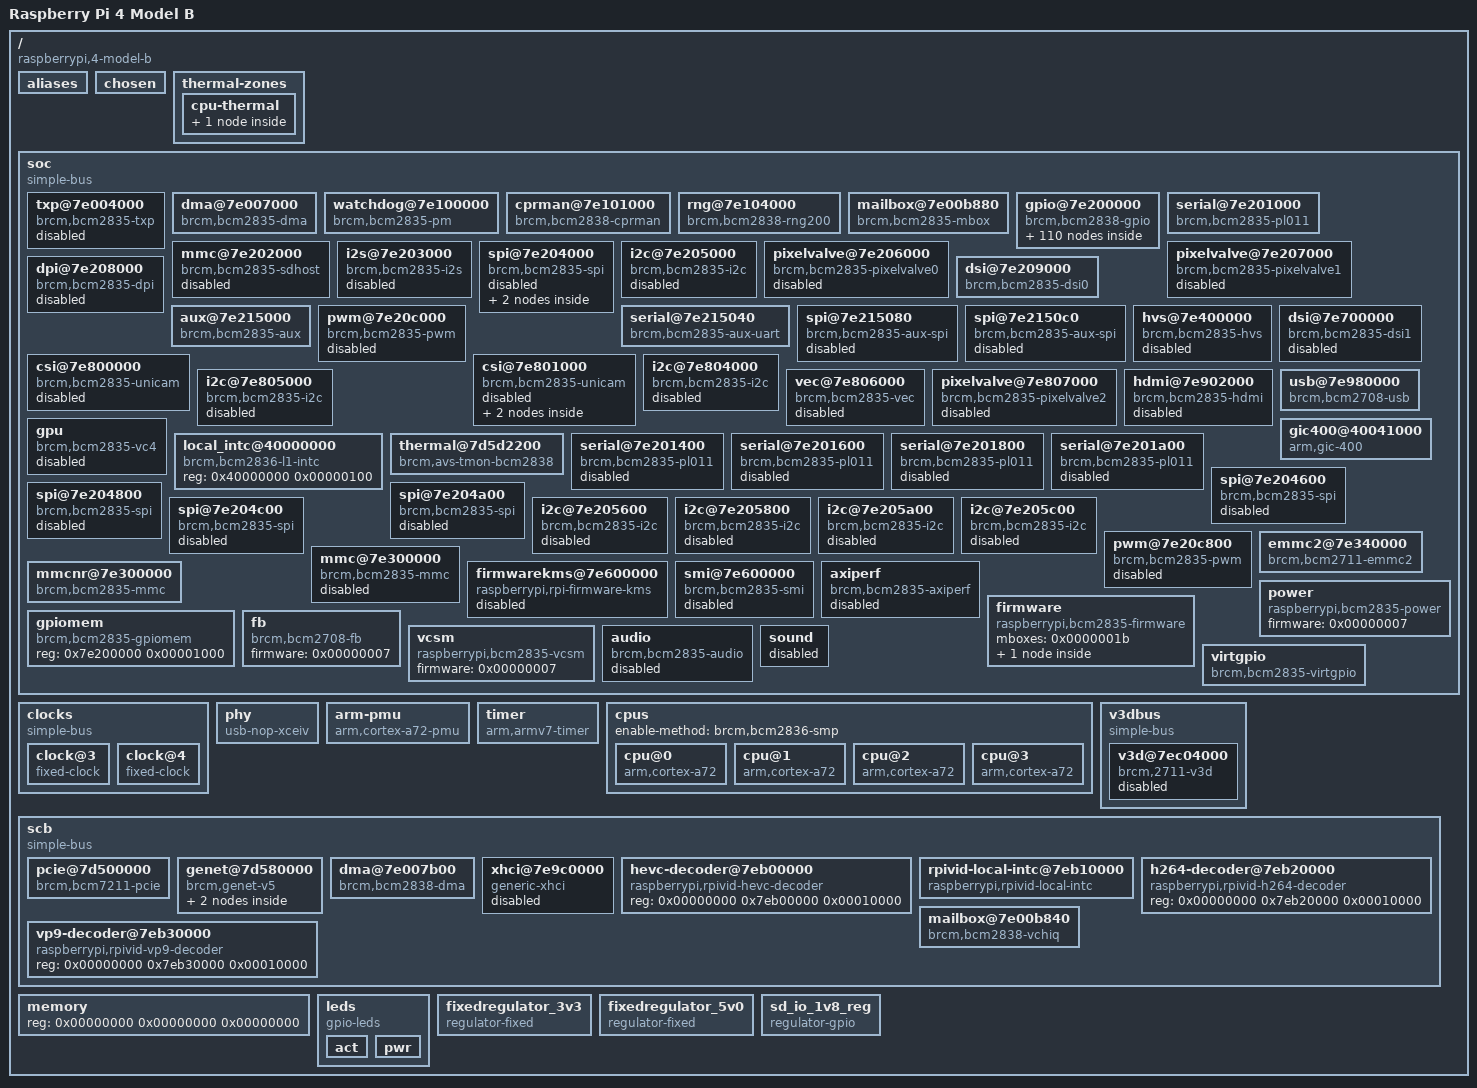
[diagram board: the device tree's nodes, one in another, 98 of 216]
/dts-v1/;
// version:		17
// last_comp_version:	16
// boot_cpuid_phys:	0x0

/memreserve/ 0 0x1000;
/ {
    compatible = "raspberrypi,4-model-b", "brcm,bcm2838";
    model = "Raspberry Pi 4 Model B";
    interrupt-parent = <0x00000001>;
    #address-cells = <0x00000002>;
    #size-cells = <0x00000001>;
    aliases {
        serial0 = "/soc/serial@7e215040";
        serial1 = "/soc/serial@7e201000";
        audio = "/soc/audio";
        aux = "/soc/aux@7e215000";
        sound = "/soc/sound";
        soc = "/soc";
        dma = "/soc/dma@7e007000";
        watchdog = "/soc/watchdog@7e100000";
        random = "/soc/rng@7e104000";
        mailbox = "/soc/mailbox@7e00b880";
        gpio = "/soc/gpio@7e200000";
        uart0 = "/soc/serial@7e201000";
        sdhost = "/soc/mmc@7e202000";
        mmc0 = "/soc/emmc2@7e340000";
        i2s = "/soc/i2s@7e203000";
        spi0 = "/soc/spi@7e204000";
        i2c0 = "/soc/i2c@7e205000";
        uart1 = "/soc/serial@7e215040";
        spi1 = "/soc/spi@7e215080";
        spi2 = "/soc/spi@7e2150c0";
        mmc = "/soc/mmc@7e300000";
        mmc1 = "/soc/mmcnr@7e300000";
        i2c1 = "/soc/i2c@7e804000";
        i2c2 = "/soc/i2c@7e805000";
        usb = "/soc/usb@7e980000";
        leds = "/leds";
        fb = "/soc/fb";
        thermal = "/soc/thermal@7d5d2200";
        axiperf = "/soc/axiperf";
        mmc2 = "/soc/mmc@7e202000";
        i2c3 = "/soc/i2c@7e205600";
        i2c4 = "/soc/i2c@7e205800";
        i2c5 = "/soc/i2c@7e205a00";
        i2c6 = "/soc/i2c@7e205c00";
        ethernet0 = "/scb/genet@7d580000";
    };
    chosen {
        bootargs = "coherent_pool=1M 8250.nr_uarts=1 cma=64M";
    };
    thermal-zones {
        cpu-thermal {
            polling-delay-passive = <0x00000000>;
            polling-delay = <0x000003e8>;
            thermal-sensors = <0x00000002>;
            coefficients = <0xfffffe19 0x000641b8>;
            phandle = <0x00000034>;
            cooling-maps {
            };
        };
    };
    soc {
        compatible = "simple-bus";
        #address-cells = <0x00000001>;
        #size-cells = <0x00000001>;
        ranges = <0x7e000000 0x00000000 0xfe000000 0x01800000 0x7c000000 0x00000000 0xfc000000 0x02000000 0x40000000 0x00000000 0xff800000 0x00800000>;
        dma-ranges = <0xc0000000 0x00000000 0x00000000 0x3c000000>;
        phandle = <0x00000035>;
        txp@7e004000 {
            compatible = "brcm,bcm2835-txp";
            reg = <0x7e004000 0x00000020>;
            interrupts = <0x00000000 0x0000004b 0x00000004>;
            status = "disabled";
            phandle = <0x00000036>;
        };
        dma@7e007000 {
            compatible = "brcm,bcm2835-dma";
            reg = <0x7e007000 0x00000b00>;
            interrupts = <0x00000000 0x00000050 0x00000004 0x00000000 0x00000051 0x00000004 0x00000000 0x00000052 0x00000004 0x00000000 0x00000053 0x00000004 0x00000000 0x00000054 0x00000004 0x00000000 0x00000055 0x00000004 0x00000000 0x00000056 0x00000004 0x00000000 0x00000057 0x00000004 0x00000000 0x00000057 0x00000004 0x00000000 0x00000058 0x00000004 0x00000000 0x00000058 0x00000004>;
            interrupt-names = "dma0", "dma1", "dma2", "dma3", "dma4", "dma5", "dma6", "dma7", "dma8", "dma9", "dma10";
            #dma-cells = <0x00000001>;
            brcm,dma-channel-mask = <0x000001f5>;
            phandle = <0x0000000a>;
        };
        watchdog@7e100000 {
            compatible = "brcm,bcm2835-pm", "brcm,bcm2835-pm-wdt";
            #power-domain-cells = <0x00000001>;
            #reset-cells = <0x00000001>;
            reg = <0x7e100000 0x00000114 0x7e00a000 0x00000024 0x7ec11000 0x00000020>;
            clocks = <0x00000003 0x00000015 0x00000003 0x0000001d 0x00000003 0x00000017 0x00000003 0x00000016>;
            clock-names = "v3d", "peri_image", "h264", "isp";
            system-power-controller;
            phandle = <0x00000021>;
        };
        cprman@7e101000 {
            compatible = "brcm,bcm2838-cprman";
            #clock-cells = <0x00000001>;
            reg = <0x7e101000 0x00002000>;
            clocks = <0x00000004 0x00000005 0x00000000 0x00000005 0x00000001 0x00000005 0x00000002 0x00000006 0x00000000 0x00000006 0x00000001 0x00000006 0x00000002>;
            firmware = <0x00000007>;
            phandle = <0x00000003>;
        };
        rng@7e104000 {
            compatible = "brcm,bcm2838-rng200";
            reg = <0x7e104000 0x00000010>;
            interrupts = <0x00000000 0x0000007d 0x00000004>;
            phandle = <0x0000002b>;
        };
        mailbox@7e00b880 {
            compatible = "brcm,bcm2835-mbox";
            reg = <0x7e00b880 0x00000040>;
            interrupts = <0x00000000 0x00000021 0x00000004>;
            #mbox-cells = <0x00000000>;
            phandle = <0x0000001b>;
        };
        gpio@7e200000 {
            compatible = "brcm,bcm2838-gpio", "brcm,bcm2835-gpio";
            reg = <0x7e200000 0x000000b4>;
            interrupts = <0x00000000 0x00000071 0x00000004 0x00000000 0x00000072 0x00000004>;
            gpio-controller;
            #gpio-cells = <0x00000002>;
            interrupt-controller;
            #interrupt-cells = <0x00000002>;
            pinctrl-names = "default";
            phandle = <0x0000000f>;
            dpi_gpio0 {
                brcm,pins = <0x00000000 0x00000001 0x00000002 0x00000003 0x00000004 0x00000005 0x00000006 0x00000007 0x00000008 0x00000009 0x0000000a 0x0000000b 0x0000000c 0x0000000d 0x0000000e 0x0000000f 0x00000010 0x00000011 0x00000012 0x00000013 0x00000014 0x00000015 0x00000016 0x00000017 0x00000018 0x00000019 0x0000001a 0x0000001b>;
                brcm,function = <0x00000006>;
                phandle = <0x00000037>;
            };
            emmc_gpio22 {
                brcm,pins = <0x00000016 0x00000017 0x00000018 0x00000019 0x0000001a 0x0000001b>;
                brcm,function = <0x00000007>;
                phandle = <0x00000038>;
            };
            emmc_gpio34 {
                brcm,pins = <0x00000022 0x00000023 0x00000024 0x00000025 0x00000026 0x00000027>;
                brcm,function = <0x00000007>;
                brcm,pull = <0x00000000 0x00000002 0x00000002 0x00000002 0x00000002 0x00000002>;
                phandle = <0x00000039>;
            };
            emmc_gpio48 {
                brcm,pins = <0x00000030 0x00000031 0x00000032 0x00000033 0x00000034 0x00000035>;
                brcm,function = <0x00000007>;
                phandle = <0x00000019>;
            };
            gpclk0_gpio4 {
                brcm,pins = <0x00000004>;
                brcm,function = <0x00000004>;
                phandle = <0x0000003a>;
            };
            gpclk1_gpio5 {
                brcm,pins = <0x00000005>;
                brcm,function = <0x00000004>;
                phandle = <0x0000003b>;
            };
            gpclk1_gpio42 {
                brcm,pins = <0x0000002a>;
                brcm,function = <0x00000004>;
                phandle = <0x0000003c>;
            };
            gpclk1_gpio44 {
                brcm,pins = <0x0000002c>;
                brcm,function = <0x00000004>;
                phandle = <0x0000003d>;
            };
            gpclk2_gpio6 {
                brcm,pins = <0x00000006>;
                brcm,function = <0x00000004>;
                phandle = <0x0000003e>;
            };
            gpclk2_gpio43 {
                brcm,pins = <0x0000002b>;
                brcm,function = <0x00000004>;
                brcm,pull = <0x00000000>;
                phandle = <0x0000003f>;
            };
            i2c0_gpio0 {
                brcm,pins = <0x00000000 0x00000001>;
                brcm,function = <0x00000004>;
                phandle = <0x00000040>;
            };
            i2c0_gpio28 {
                brcm,pins = <0x0000001c 0x0000001d>;
                brcm,function = <0x00000004>;
                phandle = <0x00000041>;
            };
            i2c0_gpio44 {
                brcm,pins = <0x0000002c 0x0000002d>;
                brcm,function = <0x00000005>;
                phandle = <0x00000042>;
            };
            i2c1_gpio2 {
                brcm,pins = <0x00000002 0x00000003>;
                brcm,function = <0x00000004>;
                phandle = <0x00000043>;
            };
            i2c1_gpio44 {
                brcm,pins = <0x0000002c 0x0000002d>;
                brcm,function = <0x00000006>;
                phandle = <0x00000044>;
            };
            jtag_gpio22 {
                brcm,pins = <0x00000016 0x00000017 0x00000018 0x00000019 0x0000001a 0x0000001b>;
                brcm,function = <0x00000003>;
                phandle = <0x00000045>;
            };
            pcm_gpio18 {
                brcm,pins = <0x00000012 0x00000013 0x00000014 0x00000015>;
                brcm,function = <0x00000004>;
                phandle = <0x00000046>;
            };
            pcm_gpio28 {
                brcm,pins = <0x0000001c 0x0000001d 0x0000001e 0x0000001f>;
                brcm,function = <0x00000006>;
                phandle = <0x00000047>;
            };
            pwm0_gpio12 {
                brcm,pins = <0x0000000c>;
                brcm,function = <0x00000004>;
                phandle = <0x00000048>;
            };
            pwm0_gpio18 {
                brcm,pins = <0x00000012>;
                brcm,function = <0x00000002>;
                phandle = <0x00000049>;
            };
            pwm0_gpio40 {
                brcm,pins = <0x00000028>;
                brcm,function = <0x00000004>;
                phandle = <0x0000004a>;
            };
            pwm1_gpio13 {
                brcm,pins = <0x0000000d>;
                brcm,function = <0x00000004>;
                phandle = <0x0000004b>;
            };
            pwm1_gpio19 {
                brcm,pins = <0x00000013>;
                brcm,function = <0x00000002>;
                phandle = <0x0000004c>;
            };
            pwm1_gpio41 {
                brcm,pins = <0x00000029>;
                brcm,function = <0x00000004>;
                phandle = <0x0000004d>;
            };
            pwm1_gpio45 {
                brcm,pins = <0x0000002d>;
                brcm,function = <0x00000004>;
                phandle = <0x0000004e>;
            };
            sdhost_gpio48 {
                brcm,pins = <0x00000016 0x00000017 0x00000018 0x00000019 0x0000001a 0x0000001b>;
                brcm,function = <0x00000004>;
                phandle = <0x0000000b>;
            };
            spi0_gpio7 {
                brcm,pins = <0x00000007 0x00000008 0x00000009 0x0000000a 0x0000000b>;
                brcm,function = <0x00000004>;
                phandle = <0x0000004f>;
            };
            spi0_gpio35 {
                brcm,pins = <0x00000023 0x00000024 0x00000025 0x00000026 0x00000027>;
                brcm,function = <0x00000004>;
                phandle = <0x00000050>;
            };
            spi1_gpio16 {
                brcm,pins = <0x00000010 0x00000011 0x00000012 0x00000013 0x00000014 0x00000015>;
                brcm,function = <0x00000003>;
                phandle = <0x00000051>;
            };
            spi2_gpio40 {
                brcm,pins = <0x00000028 0x00000029 0x0000002a 0x0000002b 0x0000002c 0x0000002d>;
                brcm,function = <0x00000003>;
                phandle = <0x00000052>;
            };
            uart0_gpio14 {
                brcm,pins = <0x0000000e 0x0000000f>;
                brcm,function = <0x00000004>;
                phandle = <0x00000053>;
            };
            uart0_ctsrts_gpio16 {
                brcm,pins = <0x00000010 0x00000011>;
                brcm,function = <0x00000007>;
                phandle = <0x00000054>;
            };
            uart0_ctsrts_gpio30 {
                brcm,pins = <0x0000001e 0x0000001f>;
                brcm,function = <0x00000007>;
                brcm,pull = <0x00000002 0x00000000>;
                phandle = <0x00000055>;
            };
            uart0_gpio32 {
                brcm,pins = <0x00000020 0x00000021>;
                brcm,function = <0x00000007>;
                brcm,pull = <0x00000000 0x00000002>;
                phandle = <0x00000056>;
            };
            uart0_gpio36 {
                brcm,pins = <0x00000024 0x00000025>;
                brcm,function = <0x00000006>;
                phandle = <0x00000057>;
            };
            uart0_ctsrts_gpio38 {
                brcm,pins = <0x00000026 0x00000027>;
                brcm,function = <0x00000006>;
                phandle = <0x00000058>;
            };
            uart1_gpio14 {
                brcm,pins = <0x0000000e 0x0000000f>;
                brcm,function = <0x00000002>;
                phandle = <0x00000059>;
            };
            uart1_ctsrts_gpio16 {
                brcm,pins = <0x00000010 0x00000011>;
                brcm,function = <0x00000002>;
                phandle = <0x0000005a>;
            };
            uart1_gpio32 {
                brcm,pins = <0x00000020 0x00000021>;
                brcm,function = <0x00000002>;
                phandle = <0x0000005b>;
            };
            uart1_ctsrts_gpio30 {
                brcm,pins = <0x0000001e 0x0000001f>;
                brcm,function = <0x00000002>;
                phandle = <0x0000005c>;
            };
            uart1_gpio40 {
                brcm,pins = <0x00000028 0x00000029>;
                brcm,function = <0x00000002>;
                phandle = <0x0000005d>;
            };
            uart1_ctsrts_gpio42 {
                brcm,pins = <0x0000002a 0x0000002b>;
                brcm,function = <0x00000002>;
                phandle = <0x0000005e>;
            };
            gpclk0_gpio49 {
                brcm,pins = <0x00000031>;
                brcm,function = <0x00000005>;
                brcm,pull = <0x00000000>;
                phandle = <0x0000005f>;
            };
            gpclk1_gpio50 {
                brcm,pins = <0x00000032>;
                brcm,function = <0x00000005>;
                brcm,pull = <0x00000000>;
                phandle = <0x00000060>;
            };
            gpclk2_gpio51 {
                brcm,pins = <0x00000033>;
                brcm,function = <0x00000005>;
                brcm,pull = <0x00000000>;
                phandle = <0x00000061>;
            };
            i2c0_gpio46 {
                brcm,pins = <0x0000002e 0x0000002f>;
                brcm,function = <0x00000004>;
                phandle = <0x00000062>;
            };
            i2c1_gpio46 {
                brcm,pins = <0x0000002e 0x0000002f>;
                brcm,function = <0x00000005>;
                phandle = <0x00000063>;
            };
            i2c3_gpio2 {
                brcm,pins = <0x00000002 0x00000003>;
                brcm,function = <0x00000002>;
                phandle = <0x00000064>;
            };
            i2c3_gpio4 {
                brcm,pins = <0x00000004 0x00000005>;
                brcm,function = <0x00000002>;
                phandle = <0x00000065>;
            };
            i2c4_gpio6 {
                brcm,pins = <0x00000006 0x00000007>;
                brcm,function = <0x00000002>;
                phandle = <0x00000066>;
            };
            i2c4_gpio8 {
                brcm,pins = <0x00000008 0x00000009>;
                brcm,function = <0x00000002>;
                phandle = <0x00000067>;
            };
            i2c5_gpio10 {
                brcm,pins = <0x0000000a 0x0000000b>;
                brcm,function = <0x00000002>;
                phandle = <0x00000068>;
            };
            i2c5_gpio12 {
                brcm,pins = <0x0000000c 0x0000000d>;
                brcm,function = <0x00000002>;
                phandle = <0x00000069>;
            };
            i2c6_gpio0 {
                brcm,pins = <0x00000000 0x00000001>;
                brcm,function = <0x00000002>;
                phandle = <0x0000006a>;
            };
            i2c6_gpio22 {
                brcm,pins = <0x00000016 0x00000017>;
                brcm,function = <0x00000002>;
                phandle = <0x0000006b>;
            };
            i2c_slave_gpio8 {
                brcm,pins = <0x00000008 0x00000009 0x0000000a 0x0000000b>;
                brcm,function = <0x00000007>;
                phandle = <0x0000006c>;
            };
            jtag_gpio48 {
                brcm,pins = <0x00000030 0x00000031 0x00000032 0x00000033 0x00000034 0x00000035>;
                brcm,function = <0x00000003>;
                phandle = <0x0000006d>;
            };
            mii_gpio28 {
                brcm,pins = <0x0000001c 0x0000001d 0x0000001e 0x0000001f>;
                brcm,function = <0x00000003>;
                phandle = <0x0000006e>;
            };
            mii_gpio36 {
                brcm,pins = <0x00000024 0x00000025 0x00000026 0x00000027>;
                brcm,function = <0x00000002>;
                phandle = <0x0000006f>;
            };
            pcm_gpio50 {
                brcm,pins = <0x00000032 0x00000033 0x00000034 0x00000035>;
                brcm,function = <0x00000006>;
                phandle = <0x00000070>;
            };
            pwm0_gpio52 {
                brcm,pins = <0x00000034>;
                brcm,function = <0x00000005>;
                brcm,pull = <0x00000000>;
                phandle = <0x00000071>;
            };
            pwm1_gpio53 {
                brcm,pins = <0x00000035>;
                brcm,function = <0x00000005>;
                brcm,pull = <0x00000000>;
                phandle = <0x00000072>;
            };
            rgmii_gpio35 {
                brcm,pins = <0x00000023 0x00000024>;
                brcm,function = <0x00000003>;
                phandle = <0x00000073>;
            };
            rgmii_irq_gpio34 {
                brcm,pins = <0x00000022>;
                brcm,function = <0x00000002>;
                phandle = <0x00000074>;
            };
            rgmii_irq_gpio39 {
                brcm,pins = <0x00000027>;
                brcm,function = <0x00000003>;
                phandle = <0x00000075>;
            };
            rgmii_mdio_gpio28 {
                brcm,pins = <0x0000001c 0x0000001d>;
                brcm,function = <0x00000002>;
                phandle = <0x00000076>;
            };
            rgmii_mdio_gpio37 {
                brcm,pins = <0x00000025 0x00000026>;
                brcm,function = <0x00000003>;
                phandle = <0x00000077>;
            };
            spi0_gpio46 {
                brcm,pins = <0x0000002e 0x0000002f 0x00000030 0x00000031>;
                brcm,function = <0x00000006>;
                phandle = <0x00000078>;
            };
            spi2_gpio46 {
                brcm,pins = <0x0000002e 0x0000002f 0x00000030 0x00000031 0x00000032>;
                brcm,function = <0x00000002>;
                phandle = <0x00000079>;
            };
            spi3_gpio0 {
                brcm,pins = <0x00000000 0x00000001 0x00000002 0x00000003>;
                brcm,function = <0x00000007>;
                phandle = <0x0000007a>;
            };
            spi4_gpio4 {
                brcm,pins = <0x00000004 0x00000005 0x00000006 0x00000007>;
                brcm,function = <0x00000007>;
                phandle = <0x0000007b>;
            };
            spi5_gpio12 {
                brcm,pins = <0x0000000c 0x0000000d 0x0000000e 0x0000000f>;
                brcm,function = <0x00000007>;
                phandle = <0x0000007c>;
            };
            spi6_gpio18 {
                brcm,pins = <0x00000012 0x00000013 0x00000014 0x00000015>;
                brcm,function = <0x00000007>;
                phandle = <0x0000007d>;
            };
            uart2_gpio0 {
                brcm,pins = <0x00000000 0x00000001>;
                brcm,function = <0x00000003>;
                brcm,pull = <0x00000000 0x00000002>;
                phandle = <0x0000007e>;
            };
            uart2_ctsrts_gpio2 {
                brcm,pins = <0x00000002 0x00000003>;
                brcm,function = <0x00000003>;
                brcm,pull = <0x00000002 0x00000000>;
                phandle = <0x0000007f>;
            };
            uart3_gpio4 {
                brcm,pins = <0x00000004 0x00000005>;
                brcm,function = <0x00000003>;
                brcm,pull = <0x00000000 0x00000002>;
                phandle = <0x00000080>;
            };
            uart3_ctsrts_gpio6 {
                brcm,pins = <0x00000006 0x00000007>;
                brcm,function = <0x00000003>;
                brcm,pull = <0x00000002 0x00000000>;
                phandle = <0x00000081>;
            };
            uart4_gpio8 {
                brcm,pins = <0x00000008 0x00000009>;
                brcm,function = <0x00000003>;
                brcm,pull = <0x00000000 0x00000002>;
                phandle = <0x00000082>;
            };
            uart4_ctsrts_gpio10 {
                brcm,pins = <0x0000000a 0x0000000b>;
                brcm,function = <0x00000003>;
                brcm,pull = <0x00000002 0x00000000>;
                phandle = <0x00000083>;
            };
            uart5_gpio12 {
                brcm,pins = <0x0000000c 0x0000000d>;
                brcm,function = <0x00000003>;
                brcm,pull = <0x00000000 0x00000002>;
                phandle = <0x00000084>;
            };
            uart5_ctsrts_gpio14 {
                brcm,pins = <0x0000000e 0x0000000f>;
                brcm,function = <0x00000003>;
                brcm,pull = <0x00000002 0x00000000>;
                phandle = <0x00000085>;
            };
            dpi_18bit_gpio0 {
                brcm,pins = <0x00000000 0x00000001 0x00000002 0x00000003 0x00000004 0x00000005 0x00000006 0x00000007 0x00000008 0x00000009 0x0000000a 0x0000000b 0x0000000c 0x0000000d 0x0000000e 0x0000000f 0x00000010 0x00000011 0x00000012 0x00000013 0x00000014 0x00000015>;
                brcm,function = <0x00000006>;
                phandle = <0x00000086>;
            };
            gpioout {
                brcm,pins = <0x00000006>;
                brcm,function = <0x00000001>;
                phandle = <0x00000087>;
            };
            alt0 {
                brcm,pins = <0x00000004 0x00000005 0x00000007 0x00000008 0x00000009 0x0000000a 0x0000000b>;
                brcm,function = <0x00000004>;
                phandle = <0x00000088>;
            };
            spi0_pins {
                brcm,pins = <0x00000009 0x0000000a 0x0000000b>;
                brcm,function = <0x00000004>;
                phandle = <0x0000000d>;
            };
            spi0_cs_pins {
                brcm,pins = <0x00000008 0x00000007>;
                brcm,function = <0x00000001>;
                phandle = <0x0000000e>;
            };
            spi3_pins {
                brcm,pins = <0x00000001 0x00000002 0x00000003>;
                brcm,function = <0x00000007>;
                phandle = <0x00000089>;
            };
            spi3_cs_pins {
                brcm,pins = <0x00000000 0x00000018>;
                brcm,function = <0x00000001>;
                phandle = <0x0000008a>;
            };
            spi4_pins {
                brcm,pins = <0x00000005 0x00000006 0x00000007>;
                brcm,function = <0x00000007>;
                phandle = <0x0000008b>;
            };
            spi4_cs_pins {
                brcm,pins = <0x00000004 0x00000019>;
                brcm,function = <0x00000001>;
                phandle = <0x0000008c>;
            };
            spi5_pins {
                brcm,pins = <0x0000000d 0x0000000e 0x0000000f>;
                brcm,function = <0x00000007>;
                phandle = <0x0000008d>;
            };
            spi5_cs_pins {
                brcm,pins = <0x0000000c 0x0000001a>;
                brcm,function = <0x00000001>;
                phandle = <0x0000008e>;
            };
            spi6_pins {
                brcm,pins = <0x00000013 0x00000014 0x00000015>;
                brcm,function = <0x00000007>;
                phandle = <0x0000008f>;
            };
            spi6_cs_pins {
                brcm,pins = <0x00000012 0x0000001b>;
                brcm,function = <0x00000001>;
                phandle = <0x00000090>;
            };
            i2c0 {
                brcm,pins = <0x00000000 0x00000001>;
                brcm,function = <0x00000004>;
                brcm,pull = <0x00000002>;
                phandle = <0x00000010>;
            };
            i2c1 {
                brcm,pins = <0x00000002 0x00000003>;
                brcm,function = <0x00000004>;
                brcm,pull = <0x00000002>;
                phandle = <0x00000014>;
            };
            i2c3 {
                brcm,pins = <0x00000004 0x00000005>;
                brcm,function = <0x00000002>;
                brcm,pull = <0x00000002>;
                phandle = <0x00000091>;
            };
            i2c4 {
                brcm,pins = <0x00000008 0x00000009>;
                brcm,function = <0x00000002>;
                brcm,pull = <0x00000002>;
                phandle = <0x00000092>;
            };
            i2c5 {
                brcm,pins = <0x0000000c 0x0000000d>;
                brcm,function = <0x00000002>;
                brcm,pull = <0x00000002>;
                phandle = <0x00000093>;
            };
            i2c6 {
                brcm,pins = <0x00000016 0x00000017>;
                brcm,function = <0x00000002>;
                brcm,pull = <0x00000002>;
                phandle = <0x00000094>;
            };
            i2s {
                brcm,pins = <0x00000012 0x00000013 0x00000014 0x00000015>;
                brcm,function = <0x00000004>;
                phandle = <0x0000000c>;
            };
            sdio_pins {
                brcm,pins = <0x00000022 0x00000023 0x00000024 0x00000025 0x00000026 0x00000027>;
                brcm,function = <0x00000007>;
                brcm,pull = <0x00000000 0x00000002 0x00000002 0x00000002 0x00000002 0x00000002>;
                phandle = <0x0000001a>;
            };
            bt_pins {
                brcm,pins = "-";
                brcm,function = <0x00000000>;
                brcm,pull = <0x00000002>;
                phandle = <0x00000009>;
            };
            uart0_pins {
                brcm,pins = <0x00000020 0x00000021>;
                brcm,function = <0x00000007>;
                brcm,pull = <0x00000000 0x00000002>;
                phandle = <0x00000008>;
            };
            uart1_pins {
                brcm,pins;
                brcm,function;
                brcm,pull;
                phandle = <0x00000013>;
            };
            uart2_pins {
                brcm,pins = <0x00000000 0x00000001>;
                brcm,function = <0x00000003>;
                brcm,pull = <0x00000000 0x00000002>;
                phandle = <0x00000095>;
            };
            uart3_pins {
                brcm,pins = <0x00000004 0x00000005>;
                brcm,function = <0x00000003>;
                brcm,pull = <0x00000000 0x00000002>;
                phandle = <0x00000096>;
            };
            uart4_pins {
                brcm,pins = <0x00000008 0x00000009>;
                brcm,function = <0x00000003>;
                brcm,pull = <0x00000000 0x00000002>;
                phandle = <0x00000097>;
            };
            uart5_pins {
                brcm,pins = <0x0000000c 0x0000000d>;
                brcm,function = <0x00000003>;
                brcm,pull = <0x00000000 0x00000002>;
                phandle = <0x00000098>;
            };
            audio_pins {
                brcm,pins = <0x00000028 0x00000029>;
                brcm,function = <0x00000004>;
                phandle = <0x0000001c>;
            };
        };
        serial@7e201000 {
            compatible = "brcm,bcm2835-pl011", "arm,pl011", "arm,primecell";
            reg = <0x7e201000 0x00000200>;
            interrupts = <0x00000000 0x00000079 0x00000004>;
            clocks = <0x00000003 0x00000013 0x00000003 0x00000014>;
            clock-names = "uartclk", "apb_pclk";
            arm,primecell-periphid = <0x00241011>;
            cts-event-workaround;
            pinctrl-names = "default";
            pinctrl-0 = <0x00000008 0x00000009>;
            status = "okay";
            phandle = <0x00000024>;
        };
        mmc@7e202000 {
            compatible = "brcm,bcm2835-sdhost";
            reg = <0x7e202000 0x00000100>;
            interrupts = <0x00000000 0x00000078 0x00000004>;
            clocks = <0x00000003 0x00000014>;
            dmas = <0x0000000a 0x2000000d>;
            dma-names = "rx-tx";
            status = "disabled";
            pinctrl-names = "default";
            pinctrl-0 = <0x0000000b>;
            bus-width = <0x00000004>;
            brcm,overclock-50 = <0x00000000>;
            brcm,pio-limit = <0x00000001>;
            phandle = <0x0000002c>;
        };
        i2s@7e203000 {
            compatible = "brcm,bcm2835-i2s";
            reg = <0x7e203000 0x00000024>;
            clocks = <0x00000003 0x0000001f>;
            dmas = <0x0000000a 0x00000002 0x0000000a 0x00000003>;
            dma-names = "tx", "rx";
            status = "disabled";
            #sound-dai-cells = <0x00000000>;
            pinctrl-names = "default";
            pinctrl-0 = <0x0000000c>;
            phandle = <0x00000026>;
        };
        spi@7e204000 {
            compatible = "brcm,bcm2835-spi";
            reg = <0x7e204000 0x00000200>;
            interrupts = <0x00000000 0x00000076 0x00000004>;
            clocks = <0x00000003 0x00000014>;
            #address-cells = <0x00000001>;
            #size-cells = <0x00000000>;
            status = "disabled";
            dmas = <0x0000000a 0x00000006 0x0000000a 0x00000007>;
            dma-names = "tx", "rx";
            pinctrl-names = "default";
            pinctrl-0 = <0x0000000d 0x0000000e>;
            cs-gpios = <0x0000000f 0x00000008 0x00000001 0x0000000f 0x00000007 0x00000001>;
            phandle = <0x00000027>;
            spidev@0 {
                compatible = "spidev";
                reg = <0x00000000>;
                #address-cells = <0x00000001>;
                #size-cells = <0x00000000>;
                spi-max-frequency = <0x07735940>;
                phandle = <0x00000099>;
            };
            spidev@1 {
                compatible = "spidev";
                reg = <0x00000001>;
                #address-cells = <0x00000001>;
                #size-cells = <0x00000000>;
                spi-max-frequency = <0x07735940>;
                phandle = <0x0000009a>;
            };
        };
        i2c@7e205000 {
            compatible = "brcm,bcm2835-i2c";
            reg = <0x7e205000 0x00000200>;
            interrupts = <0x00000000 0x00000075 0x00000004>;
            clocks = <0x00000003 0x00000014>;
            #address-cells = <0x00000001>;
            #size-cells = <0x00000000>;
            status = "disabled";
            pinctrl-names = "default";
            pinctrl-0 = <0x00000010>;
            clock-frequency = <0x000186a0>;
            phandle = <0x00000028>;
        };
        pixelvalve@7e206000 {
            compatible = "brcm,bcm2835-pixelvalve0";
            reg = <0x7e206000 0x00000100>;
            interrupts = <0x00000000 0x0000006d 0x00000004>;
            status = "disabled";
            phandle = <0x0000009b>;
        };
        pixelvalve@7e207000 {
            compatible = "brcm,bcm2835-pixelvalve1";
            reg = <0x7e207000 0x00000100>;
            interrupts = <0x00000000 0x0000006e 0x00000004>;
            status = "disabled";
            phandle = <0x0000009c>;
        };
        dpi@7e208000 {
            compatible = "brcm,bcm2835-dpi";
            reg = <0x7e208000 0x0000008c>;
            clocks = <0x00000003 0x00000014 0x00000003 0x0000002c>;
            clock-names = "core", "pixel";
            #address-cells = <0x00000001>;
            #size-cells = <0x00000000>;
            status = "disabled";
            phandle = <0x0000009d>;
        };
        dsi@7e209000 {
            compatible = "brcm,bcm2835-dsi0";
            reg = <0x7e209000 0x00000078>;
            interrupts = <0x00000000 0x00000064 0x00000004>;
            #address-cells = <0x00000001>;
            #size-cells = <0x00000000>;
            #clock-cells = <0x00000001>;
            clocks = <0x00000003 0x00000020 0x00000003 0x0000002f 0x00000003 0x00000031>;
            clock-names = "phy", "escape", "pixel";
            clock-output-names = "dsi0_byte", "dsi0_ddr2", "dsi0_ddr";
            power-domains = <0x00000011 0x00000011>;
            phandle = <0x00000005>;
        };
        aux@7e215000 {
            compatible = "brcm,bcm2835-aux";
            #clock-cells = <0x00000001>;
            reg = <0x7e215000 0x00000008>;
            clocks = <0x00000003 0x00000014>;
            phandle = <0x00000012>;
        };
        serial@7e215040 {
            compatible = "brcm,bcm2835-aux-uart";
            reg = <0x7e215040 0x00000040>;
            interrupts = <0x00000000 0x0000005d 0x00000004>;
            clocks = <0x00000012 0x00000000>;
            status = "okay";
            pinctrl-names = "default";
            pinctrl-0 = <0x00000013>;
            phandle = <0x00000025>;
        };
        spi@7e215080 {
            compatible = "brcm,bcm2835-aux-spi";
            reg = <0x7e215080 0x00000040>;
            interrupts = <0x00000000 0x0000005d 0x00000004>;
            clocks = <0x00000012 0x00000001>;
            #address-cells = <0x00000001>;
            #size-cells = <0x00000000>;
            status = "disabled";
            phandle = <0x0000009e>;
        };
        spi@7e2150c0 {
            compatible = "brcm,bcm2835-aux-spi";
            reg = <0x7e2150c0 0x00000040>;
            interrupts = <0x00000000 0x0000005d 0x00000004>;
            clocks = <0x00000012 0x00000002>;
            #address-cells = <0x00000001>;
            #size-cells = <0x00000000>;
            status = "disabled";
            phandle = <0x0000009f>;
        };
        pwm@7e20c000 {
            compatible = "brcm,bcm2835-pwm";
            reg = <0x7e20c000 0x00000028>;
            clocks = <0x00000003 0x0000001e>;
            assigned-clocks = <0x00000003 0x0000001e>;
            assigned-clock-rates = <0x00989680>;
            #pwm-cells = <0x00000002>;
            status = "disabled";
            phandle = <0x000000a0>;
        };
        hvs@7e400000 {
            compatible = "brcm,bcm2835-hvs";
            reg = <0x7e400000 0x00006000>;
            interrupts = <0x00000000 0x00000061 0x00000004>;
            status = "disabled";
            phandle = <0x000000a1>;
        };
        dsi@7e700000 {
            compatible = "brcm,bcm2835-dsi1";
            reg = <0x7e700000 0x0000008c>;
            interrupts = <0x00000000 0x0000006c 0x00000004>;
            #address-cells = <0x00000001>;
            #size-cells = <0x00000000>;
            #clock-cells = <0x00000001>;
            clocks = <0x00000003 0x00000023 0x00000003 0x00000030 0x00000003 0x00000032>;
            clock-names = "phy", "escape", "pixel";
            clock-output-names = "dsi1_byte", "dsi1_ddr2", "dsi1_ddr";
            status = "disabled";
            power-domains = <0x00000011 0x00000012>;
            phandle = <0x00000006>;
        };
        csi@7e800000 {
            compatible = "brcm,bcm2835-unicam";
            reg = <0x7e800000 0x00000800 0x7e802000 0x00000004>;
            interrupts = <0x00000000 0x00000066 0x00000004>;
            clocks = <0x00000003 0x0000002d>;
            clock-names = "lp";
            #address-cells = <0x00000001>;
            #size-cells = <0x00000000>;
            #clock-cells = <0x00000001>;
            status = "disabled";
            power-domains = <0x00000011 0x0000000c>;
            phandle = <0x000000a2>;
        };
        csi@7e801000 {
            compatible = "brcm,bcm2835-unicam";
            reg = <0x7e801000 0x00000800 0x7e802004 0x00000004>;
            interrupts = <0x00000000 0x00000067 0x00000004>;
            clocks = <0x00000003 0x0000002e>;
            clock-names = "lp";
            #address-cells = <0x00000001>;
            #size-cells = <0x00000000>;
            #clock-cells = <0x00000001>;
            status = "disabled";
            power-domains = <0x00000011 0x0000000d>;
            phandle = <0x000000a3>;
            port {
                endpoint {
                    data-lanes = <0x00000001 0x00000002>;
                };
            };
        };
        i2c@7e804000 {
            compatible = "brcm,bcm2835-i2c";
            reg = <0x7e804000 0x00001000>;
            interrupts = <0x00000000 0x00000075 0x00000004>;
            clocks = <0x00000003 0x00000014>;
            #address-cells = <0x00000001>;
            #size-cells = <0x00000000>;
            status = "disabled";
            pinctrl-names = "default";
            pinctrl-0 = <0x00000014>;
            clock-frequency = <0x000186a0>;
            phandle = <0x00000029>;
        };
        i2c@7e805000 {
            compatible = "brcm,bcm2835-i2c";
            reg = <0x7e805000 0x00001000>;
            interrupts = <0x00000000 0x00000075 0x00000004>;
            clocks = <0x00000003 0x00000014>;
            #address-cells = <0x00000001>;
            #size-cells = <0x00000000>;
            status = "disabled";
            clock-frequency = <0x000186a0>;
            phandle = <0x00000015>;
        };
        vec@7e806000 {
            compatible = "brcm,bcm2835-vec";
            reg = <0x7e806000 0x00001000>;
            clocks = <0x00000003 0x00000018>;
            interrupts = <0x00000000 0x0000007b 0x00000004>;
            status = "disabled";
            power-domains = <0x00000011 0x00000007>;
            phandle = <0x000000a4>;
        };
        pixelvalve@7e807000 {
            compatible = "brcm,bcm2835-pixelvalve2";
            reg = <0x7e807000 0x00000100>;
            interrupts = <0x00000000 0x0000006a 0x00000004>;
            status = "disabled";
            phandle = <0x000000a5>;
        };
        hdmi@7e902000 {
            compatible = "brcm,bcm2835-hdmi";
            reg = <0x7e902000 0x00000600 0x7e808000 0x00000100>;
            interrupts = <0x00000000 0x00000068 0x00000004 0x00000000 0x00000069 0x00000004>;
            ddc = <0x00000015>;
            clocks = <0x00000003 0x00000010 0x00000003 0x00000019>;
            clock-names = "pixel", "hdmi";
            dmas = <0x0000000a 0x00000011>;
            dma-names = "audio-rx";
            status = "disabled";
            power-domains = <0x00000011 0x00000005>;
            phandle = <0x000000a6>;
        };
        usb@7e980000 {
            compatible = "brcm,bcm2708-usb";
            reg = <0x7e980000 0x00010000 0x7e00b200 0x00000200>;
            interrupts = <0x00000000 0x00000049 0x00000004 0x00000000 0x00000028 0x00000004>;
            #address-cells = <0x00000001>;
            #size-cells = <0x00000000>;
            clocks = <0x00000016>;
            clock-names = "otg";
            phys = <0x00000017>;
            phy-names = "usb2-phy";
            interrupt-names = "usb", "soft";
            power-domains = <0x00000011 0x00000006>;
            phandle = <0x000000a7>;
        };
        gpu {
            compatible = "brcm,bcm2835-vc4";
            status = "disabled";
            phandle = <0x000000a8>;
        };
        local_intc@40000000 {
            compatible = "brcm,bcm2836-l1-intc";
            reg = <0x40000000 0x00000100>;
            phandle = <0x000000a9>;
        };
        gic400@40041000 {
            interrupt-controller;
            #interrupt-cells = <0x00000003>;
            compatible = "arm,gic-400";
            reg = <0x40041000 0x00001000 0x40042000 0x00002000 0x40044000 0x00002000 0x40046000 0x00002000>;
            interrupts = <0x00000001 0x00000009 0x00000f04>;
            phandle = <0x00000001>;
        };
        thermal@7d5d2200 {
            compatible = "brcm,avs-tmon-bcm2838";
            reg = <0x7d5d2200 0x0000002c>;
            interrupts = <0x00000000 0x00000089 0x00000004>;
            interrupt-names = "tmon";
            clocks = <0x00000003 0x0000001b>;
            #thermal-sensor-cells = <0x00000000>;
            status = "okay";
            phandle = <0x00000002>;
        };
        serial@7e201400 {
            compatible = "brcm,bcm2835-pl011", "arm,pl011", "arm,primecell";
            reg = <0x7e201400 0x00000200>;
            interrupts = <0x00000000 0x00000079 0x00000004>;
            clocks = <0x00000003 0x00000013 0x00000003 0x00000014>;
            clock-names = "uartclk", "apb_pclk";
            arm,primecell-periphid = <0x00241011>;
            status = "disabled";
            phandle = <0x000000aa>;
        };
        serial@7e201600 {
            compatible = "brcm,bcm2835-pl011", "arm,pl011", "arm,primecell";
            reg = <0x7e201600 0x00000200>;
            interrupts = <0x00000000 0x00000079 0x00000004>;
            clocks = <0x00000003 0x00000013 0x00000003 0x00000014>;
            clock-names = "uartclk", "apb_pclk";
            arm,primecell-periphid = <0x00241011>;
            status = "disabled";
            phandle = <0x000000ab>;
        };
        serial@7e201800 {
            compatible = "brcm,bcm2835-pl011", "arm,pl011", "arm,primecell";
            reg = <0x7e201800 0x00000200>;
            interrupts = <0x00000000 0x00000079 0x00000004>;
            clocks = <0x00000003 0x00000013 0x00000003 0x00000014>;
            clock-names = "uartclk", "apb_pclk";
            arm,primecell-periphid = <0x00241011>;
            status = "disabled";
            phandle = <0x000000ac>;
        };
        serial@7e201a00 {
            compatible = "brcm,bcm2835-pl011", "arm,pl011", "arm,primecell";
            reg = <0x7e201a00 0x00000200>;
            interrupts = <0x00000000 0x00000079 0x00000004>;
            clocks = <0x00000003 0x00000013 0x00000003 0x00000014>;
            clock-names = "uartclk", "apb_pclk";
            arm,primecell-periphid = <0x00241011>;
            status = "disabled";
            phandle = <0x000000ad>;
        };
        spi@7e204600 {
            compatible = "brcm,bcm2835-spi";
            reg = <0x7e204600 0x00000200>;
            interrupts = <0x00000000 0x00000076 0x00000004>;
            clocks = <0x00000003 0x00000014>;
            #address-cells = <0x00000001>;
            #size-cells = <0x00000000>;
            status = "disabled";
            phandle = <0x000000ae>;
        };
        spi@7e204800 {
            compatible = "brcm,bcm2835-spi";
            reg = <0x7e204800 0x00000200>;
            interrupts = <0x00000000 0x00000076 0x00000004>;
            clocks = <0x00000003 0x00000014>;
            #address-cells = <0x00000001>;
            #size-cells = <0x00000000>;
            status = "disabled";
            phandle = <0x000000af>;
        };
        spi@7e204a00 {
            compatible = "brcm,bcm2835-spi";
            reg = <0x7e204a00 0x00000200>;
            interrupts = <0x00000000 0x00000076 0x00000004>;
            clocks = <0x00000003 0x00000014>;
            #address-cells = <0x00000001>;
            #size-cells = <0x00000000>;
            status = "disabled";
            phandle = <0x000000b0>;
        };
        spi@7e204c00 {
            compatible = "brcm,bcm2835-spi";
            reg = <0x7e204c00 0x00000200>;
            interrupts = <0x00000000 0x00000076 0x00000004>;
            clocks = <0x00000003 0x00000014>;
            #address-cells = <0x00000001>;
            #size-cells = <0x00000000>;
            status = "disabled";
            phandle = <0x000000b1>;
        };
        i2c@7e205600 {
            compatible = "brcm,bcm2835-i2c";
            reg = <0x7e205600 0x00000200>;
            interrupts = <0x00000000 0x00000075 0x00000004>;
            clocks = <0x00000003 0x00000014>;
            #address-cells = <0x00000001>;
            #size-cells = <0x00000000>;
            status = "disabled";
            phandle = <0x000000b2>;
        };
        i2c@7e205800 {
            compatible = "brcm,bcm2835-i2c";
            reg = <0x7e205800 0x00000200>;
            interrupts = <0x00000000 0x00000075 0x00000004>;
            clocks = <0x00000003 0x00000014>;
            #address-cells = <0x00000001>;
            #size-cells = <0x00000000>;
            status = "disabled";
            phandle = <0x000000b3>;
        };
        i2c@7e205a00 {
            compatible = "brcm,bcm2835-i2c";
            reg = <0x7e205a00 0x00000200>;
            interrupts = <0x00000000 0x00000075 0x00000004>;
            clocks = <0x00000003 0x00000014>;
            #address-cells = <0x00000001>;
            #size-cells = <0x00000000>;
            status = "disabled";
            phandle = <0x000000b4>;
        };
        i2c@7e205c00 {
            compatible = "brcm,bcm2835-i2c";
            reg = <0x7e205c00 0x00000200>;
            interrupts = <0x00000000 0x00000075 0x00000004>;
            clocks = <0x00000003 0x00000014>;
            #address-cells = <0x00000001>;
            #size-cells = <0x00000000>;
            status = "disabled";
            phandle = <0x000000b5>;
        };
        pwm@7e20c800 {
            compatible = "brcm,bcm2835-pwm";
            reg = <0x7e20c800 0x00000028>;
            clocks = <0x00000003 0x0000001e>;
            assigned-clocks = <0x00000003 0x0000001e>;
            assigned-clock-rates = <0x00989680>;
            #pwm-cells = <0x00000002>;
            status = "disabled";
            phandle = <0x000000b6>;
        };
        emmc2@7e340000 {
            compatible = "brcm,bcm2711-emmc2";
            status = "okay";
            interrupts = <0x00000000 0x0000007e 0x00000004>;
            clocks = <0x00000003 0x00000033>;
            reg = <0x7e340000 0x00000100>;
            broken-cd;
            vqmmc-supply = <0x00000018>;
            phandle = <0x000000b7>;
        };
        mmc@7e300000 {
            compatible = "brcm,bcm2835-mmc", "brcm,bcm2835-sdhci";
            reg = <0x7e300000 0x00000100>;
            interrupts = <0x00000000 0x0000007e 0x00000004>;
            clocks = <0x00000003 0x0000001c>;
            dmas = <0x0000000a 0x0000000b>;
            dma-names = "rx-tx";
            brcm,overclock-50 = <0x00000000>;
            status = "disabled";
            pinctrl-names = "default";
            pinctrl-0 = <0x00000019>;
            bus-width = <0x00000004>;
            phandle = <0x0000002d>;
        };
        mmcnr@7e300000 {
            compatible = "brcm,bcm2835-mmc", "brcm,bcm2835-sdhci";
            reg = <0x7e300000 0x00000100>;
            interrupts = <0x00000000 0x0000007e 0x00000004>;
            clocks = <0x00000003 0x0000001c>;
            dmas = <0x0000000a 0x0000000b>;
            dma-names = "rx-tx";
            brcm,overclock-50 = <0x00000000>;
            non-removable;
            status = "okay";
            pinctrl-names = "default";
            pinctrl-0 = <0x0000001a>;
            bus-width = <0x00000004>;
            phandle = <0x0000002e>;
        };
        firmwarekms@7e600000 {
            compatible = "raspberrypi,rpi-firmware-kms";
            reg = <0x7e600000 0x00000100>;
            interrupts = <0x00000000 0x00000070 0x00000004>;
            brcm,firmware = <0x00000007>;
            status = "disabled";
            phandle = <0x000000b8>;
        };
        smi@7e600000 {
            compatible = "brcm,bcm2835-smi";
            reg = <0x7e600000 0x00000100>;
            interrupts = <0x00000000 0x00000070 0x00000004>;
            clocks = <0x00000003 0x0000002a>;
            assigned-clocks = <0x00000003 0x0000002a>;
            assigned-clock-rates = <0x07735940>;
            dmas = <0x0000000a 0x00000004>;
            dma-names = "rx-tx";
            status = "disabled";
            phandle = <0x000000b9>;
        };
        axiperf {
            compatible = "brcm,bcm2835-axiperf";
            reg = <0x7e009800 0x00000100 0x7ee08000 0x00000100>;
            firmware = <0x00000007>;
            status = "disabled";
            phandle = <0x0000002f>;
        };
        firmware {
            compatible = "raspberrypi,bcm2835-firmware", "simple-bus";
            #address-cells = <0x00000000>;
            #size-cells = <0x00000000>;
            mboxes = <0x0000001b>;
            phandle = <0x00000007>;
            gpio {
                compatible = "raspberrypi,firmware-gpio";
                gpio-controller;
                #gpio-cells = <0x00000002>;
                gpio-line-names = [42 54 5f 4f 4e 00 57 4c 5f 4f 4e 00 50 57 52 5f 4c 45 44 5f 4f 46 46 00 47 4c 4f 42 41 4c 5f 52 45 53 45 54 00 56 44 44 5f 53 44 5f 49 4f 5f 53 45 4c 00 43 41 4d 5f 47 50 49 4f 00 00 00];
                status = "okay";
                phandle = <0x00000032>;
            };
        };
        power {
            compatible = "raspberrypi,bcm2835-power";
            firmware = <0x00000007>;
            #power-domain-cells = <0x00000001>;
            phandle = <0x00000011>;
        };
        gpiomem {
            compatible = "brcm,bcm2835-gpiomem";
            reg = <0x7e200000 0x00001000>;
        };
        fb {
            compatible = "brcm,bcm2708-fb";
            firmware = <0x00000007>;
            status = "okay";
            phandle = <0x000000ba>;
        };
        vcsm {
            compatible = "raspberrypi,bcm2835-vcsm";
            firmware = <0x00000007>;
            status = "okay";
            phandle = <0x000000bb>;
        };
        audio {
            compatible = "brcm,bcm2835-audio";
            brcm,pwm-channels = <0x00000008>;
            status = "disabled";
            pinctrl-names = "default";
            pinctrl-0 = <0x0000001c>;
            phandle = <0x0000002a>;
        };
        sound {
            status = "disabled";
            phandle = <0x000000bc>;
        };
        virtgpio {
            compatible = "brcm,bcm2835-virtgpio";
            gpio-controller;
            #gpio-cells = <0x00000002>;
            firmware = <0x00000007>;
            status = "okay";
            phandle = <0x000000bd>;
        };
    };
    clocks {
        compatible = "simple-bus";
        #address-cells = <0x00000001>;
        #size-cells = <0x00000000>;
        clock@3 {
            compatible = "fixed-clock";
            reg = <0x00000003>;
            #clock-cells = <0x00000000>;
            clock-output-names = "osc";
            clock-frequency = <0x0337f980>;
            phandle = <0x00000004>;
        };
        clock@4 {
            compatible = "fixed-clock";
            reg = <0x00000004>;
            #clock-cells = <0x00000000>;
            clock-output-names = "otg";
            clock-frequency = <0x1c9c3800>;
            phandle = <0x00000016>;
        };
    };
    phy {
        compatible = "usb-nop-xceiv";
        #phy-cells = <0x00000000>;
        phandle = <0x00000017>;
    };
    arm-pmu {
        compatible = "arm,cortex-a72-pmu";
        interrupts = <0x00000000 0x00000010 0x00000004 0x00000000 0x00000011 0x00000004 0x00000000 0x00000012 0x00000004 0x00000000 0x00000013 0x00000004>;
        interrupt-affinity = <0x0000001d 0x0000001e 0x0000001f 0x00000020>;
    };
    timer {
        compatible = "arm,armv7-timer";
        interrupts = <0x00000001 0x0000000d 0x00000f08 0x00000001 0x0000000e 0x00000f08 0x00000001 0x0000000b 0x00000f08 0x00000001 0x0000000a 0x00000f08>;
        arm,cpu-registers-not-fw-configured;
        always-on;
    };
    cpus {
        #address-cells = <0x00000001>;
        #size-cells = <0x00000000>;
        enable-method = "brcm,bcm2836-smp";
        phandle = <0x000000be>;
        cpu@0 {
            device_type = "cpu";
            compatible = "arm,cortex-a72";
            reg = <0x00000000>;
            enable-method = "spin-table";
            cpu-release-addr = <0x00000000 0x000000d8>;
            phandle = <0x0000001d>;
        };
        cpu@1 {
            device_type = "cpu";
            compatible = "arm,cortex-a72";
            reg = <0x00000001>;
            enable-method = "spin-table";
            cpu-release-addr = <0x00000000 0x000000e0>;
            phandle = <0x0000001e>;
        };
        cpu@2 {
            device_type = "cpu";
            compatible = "arm,cortex-a72";
            reg = <0x00000002>;
            enable-method = "spin-table";
            cpu-release-addr = <0x00000000 0x000000e8>;
            phandle = <0x0000001f>;
        };
        cpu@3 {
            device_type = "cpu";
            compatible = "arm,cortex-a72";
            reg = <0x00000003>;
            enable-method = "spin-table";
            cpu-release-addr = <0x00000000 0x000000f0>;
            phandle = <0x00000020>;
        };
    };
    v3dbus {
        compatible = "simple-bus";
        #address-cells = <0x00000001>;
        #size-cells = <0x00000001>;
        ranges = <0x7c500000 0x00000000 0xfc500000 0x03300000 0x40000000 0x00000000 0xff800000 0x00800000>;
        dma-ranges = <0x00000000 0x00000000 0x00000000 0x3c000000>;
        v3d@7ec04000 {
            compatible = "brcm,2711-v3d";
            reg = <0x7ec00000 0x00004000 0x7ec04000 0x00004000>;
            reg-names = "hub", "core0";
            power-domains = <0x00000021 0x00000001>;
            resets = <0x00000021 0x00000000>;
            clocks = <0x00000003 0x00000015>;
            interrupts = <0x00000000 0x0000004a 0x00000004>;
            status = "disabled";
            phandle = <0x000000bf>;
        };
    };
    scb {
        compatible = "simple-bus";
        #address-cells = <0x00000002>;
        #size-cells = <0x00000001>;
        ranges = <0x00000000 0x7c000000 0x00000000 0xfc000000 0x03800000 0x00000000 0x40000000 0x00000000 0xff800000 0x00800000 0x00000006 0x00000000 0x00000006 0x00000000 0x40000000 0x00000000 0x00000000 0x00000000 0x00000000 0xfc000000>;
        dma-ranges = <0x00000000 0x00000000 0x00000000 0x00000000 0xfc000000>;
        phandle = <0x000000c0>;
        pcie@7d500000 {
            reg = <0x00000000 0x7d500000 0x00009310 0x00000000 0x7e00f300 0x00000020>;
            msi-controller;
            msi-parent = <0x00000022>;
            #address-cells = <0x00000003>;
            #interrupt-cells = <0x00000001>;
            #size-cells = <0x00000002>;
            bus-range = <0x00000000 0x00000001>;
            compatible = "brcm,bcm7211-pcie", "brcm,bcm7445-pcie", "brcm,pci-plat-dev";
            max-link-speed = <0x00000002>;
            tot-num-pcie = <0x00000001>;
            linux,pci-domain = <0x00000000>;
            interrupts = <0x00000000 0x00000094 0x00000004 0x00000000 0x00000094 0x00000004>;
            interrupt-names = "pcie", "msi";
            interrupt-map-mask = <0x00000000 0x00000000 0x00000000 0x00000007>;
            interrupt-map = <0x00000000 0x00000000 0x00000000 0x00000001 0x00000001 0x00000000 0x0000008f 0x00000004 0x00000000 0x00000000 0x00000000 0x00000002 0x00000001 0x00000000 0x00000090 0x00000004 0x00000000 0x00000000 0x00000000 0x00000003 0x00000001 0x00000000 0x00000091 0x00000004 0x00000000 0x00000000 0x00000000 0x00000004 0x00000001 0x00000000 0x00000092 0x00000004>;
            ranges = <0x02000000 0x00000000 0xf8000000 0x00000006 0x00000000 0x00000000 0x04000000>;
            dma-ranges = <0x02000000 0x00000000 0x00000000 0x00000000 0x00000000 0x00000001 0x00000000>;
            status = "okay";
            phandle = <0x00000022>;
        };
        genet@7d580000 {
            compatible = "brcm,genet-v5";
            reg = <0x00000000 0x7d580000 0x00010000>;
            status = "okay";
            #address-cells = <0x00000001>;
            #size-cells = <0x00000001>;
            interrupts = <0x00000000 0x0000009d 0x00000004 0x00000000 0x0000009e 0x00000004>;
            phy-handle = <0x00000023>;
            phy-mode = "rgmii";
            phandle = <0x000000c1>;
            mdio@e14 {
                #address-cells = <0x00000000>;
                #size-cells = <0x00000001>;
                compatible = "brcm,genet-mdio-v5";
                reg = <0x00000e14 0x00000008>;
                reg-names = "mdio";
                genet-phy@0 {
                    compatible = "ethernet-phy-ieee802.3-c22";
                    max-speed = <0x000003e8>;
                    reg = <0x00000001>;
                    phandle = <0x00000023>;
                };
            };
        };
        dma@7e007b00 {
            compatible = "brcm,bcm2838-dma";
            reg = <0x00000000 0x7e007b00 0x00000400>;
            interrupts = <0x00000000 0x00000059 0x00000004 0x00000000 0x0000005a 0x00000004 0x00000000 0x0000005b 0x00000004 0x00000000 0x0000005c 0x00000004>;
            interrupt-names = "dma11", "dma12", "dma13", "dma14";
            #dma-cells = <0x00000001>;
            brcm,dma-channel-mask = <0x00007000>;
            phandle = <0x000000c2>;
        };
        xhci@7e9c0000 {
            compatible = "generic-xhci";
            status = "disabled";
            reg = <0x00000000 0x7e9c0000 0x00100000>;
            interrupts = <0x00000000 0x000000b0 0x00000004>;
            phandle = <0x000000c3>;
        };
        hevc-decoder@7eb00000 {
            compatible = "raspberrypi,rpivid-hevc-decoder";
            reg = <0x00000000 0x7eb00000 0x00010000>;
            status = "okay";
        };
        rpivid-local-intc@7eb10000 {
            compatible = "raspberrypi,rpivid-local-intc";
            reg = <0x00000000 0x7eb10000 0x00001000>;
            status = "okay";
            interrupts = <0x00000000 0x00000062 0x00000004>;
        };
        h264-decoder@7eb20000 {
            compatible = "raspberrypi,rpivid-h264-decoder";
            reg = <0x00000000 0x7eb20000 0x00010000>;
            status = "okay";
        };
        vp9-decoder@7eb30000 {
            compatible = "raspberrypi,rpivid-vp9-decoder";
            reg = <0x00000000 0x7eb30000 0x00010000>;
            status = "okay";
        };
        mailbox@7e00b840 {
            compatible = "brcm,bcm2838-vchiq";
            reg = <0x00000000 0x7e00b840 0x0000003c>;
            interrupts = <0x00000000 0x00000022 0x00000004>;
            phandle = <0x000000c4>;
        };
    };
    __overrides__ {
        cam0-pwdn-ctrl;
        cam0-pwdn;
        cam0-led-ctrl;
        cam0-led;
        arm_freq;
        cache_line_size;
        uart0 = [00 00 00 24 73 74 61 74 75 73 00];
        uart1 = [00 00 00 25 73 74 61 74 75 73 00];
        i2s = [00 00 00 26 73 74 61 74 75 73 00];
        spi = [00 00 00 27 73 74 61 74 75 73 00];
        i2c0 = [00 00 00 28 73 74 61 74 75 73 00];
        i2c1 = [00 00 00 29 73 74 61 74 75 73 00];
        i2c2_iknowwhatimdoing = [00 00 00 15 73 74 61 74 75 73 00];
        i2c0_baudrate = [00 00 00 28 63 6c 6f 63 6b 2d 66 72 65 71 75 65 6e 63 79 3a 30 00];
        i2c1_baudrate = [00 00 00 29 63 6c 6f 63 6b 2d 66 72 65 71 75 65 6e 63 79 3a 30 00];
        i2c2_baudrate = [00 00 00 15 63 6c 6f 63 6b 2d 66 72 65 71 75 65 6e 63 79 3a 30 00];
        audio = [00 00 00 2a 73 74 61 74 75 73 00];
        watchdog = [00 00 00 21 73 74 61 74 75 73 00];
        random = [00 00 00 2b 73 74 61 74 75 73 00];
        sd_overclock = <0x0000002c 0x6272636d 0x2c6f7665 0x72636c6f 0x636b2d35 0x303a3000>;
        sd_force_pio = <0x0000002c 0x6272636d 0x2c666f72 0x63652d70 0x696f3f00>;
        sd_pio_limit = [00 00 00 2c 62 72 63 6d 2c 70 69 6f 2d 6c 69 6d 69 74 3a 30 00];
        sd_debug = [00 00 00 2c 62 72 63 6d 2c 64 65 62 75 67 00];
        sdio_overclock = <0x0000002d 0x6272636d 0x2c6f7665 0x72636c6f 0x636b2d35 0x303a3000 0x0000002e 0x6272636d 0x2c6f7665 0x72636c6f 0x636b2d35 0x303a3000>;
        axiperf = [00 00 00 2f 73 74 61 74 75 73 00];
        act_led_gpio = <0x00000030 0x6770696f 0x733a3400>;
        act_led_activelow = <0x00000030 0x6770696f 0x733a3800>;
        act_led_trigger = [00 00 00 30 6c 69 6e 75 78 2c 64 65 66 61 75 6c 74 2d 74 72 69 67 67 65 72 00];
        pwr_led_gpio = <0x00000031 0x6770696f 0x733a3400>;
        pwr_led_activelow = <0x00000031 0x6770696f 0x733a3800>;
        pwr_led_trigger = [00 00 00 31 6c 69 6e 75 78 2c 64 65 66 61 75 6c 74 2d 74 72 69 67 67 65 72 00];
    };
    memory {
        device_type = "memory";
        reg = <0x00000000 0x00000000 0x00000000>;
    };
    leds {
        compatible = "gpio-leds";
        phandle = <0x000000c5>;
        act {
            label = "led0";
            default-state = "keep";
            linux,default-trigger = "mmc0";
            gpios = <0x0000000f 0x0000002a 0x00000000>;
            phandle = <0x00000030>;
        };
        pwr {
            label = "led1";
            linux,default-trigger = "default-on";
            gpios = <0x00000032 0x00000002 0x00000001>;
            phandle = <0x00000031>;
        };
    };
    fixedregulator_3v3 {
        compatible = "regulator-fixed";
        regulator-name = "3v3";
        regulator-min-microvolt = <0x00325aa0>;
        regulator-max-microvolt = <0x00325aa0>;
        regulator-always-on;
        phandle = <0x000000c6>;
    };
    fixedregulator_5v0 {
        compatible = "regulator-fixed";
        regulator-name = "5v0";
        regulator-min-microvolt = <0x004c4b40>;
        regulator-max-microvolt = <0x004c4b40>;
        regulator-always-on;
        phandle = <0x00000033>;
    };
    sd_io_1v8_reg {
        status = "okay";
        compatible = "regulator-gpio";
        vin-supply = <0x00000033>;
        regulator-name = "vdd-sd-io";
        regulator-min-microvolt = <0x001b7740>;
        regulator-max-microvolt = <0x00325aa0>;
        regulator-boot-on;
        regulator-always-on;
        regulator-settling-time-us = <0x00001388>;
        gpios = <0x00000032 0x00000004 0x00000000>;
        states = <0x001b7740 0x00000001 0x00325aa0 0x00000000>;
        phandle = <0x00000018>;
    };
    __symbols__ {
        cpu_thermal = "/thermal-zones/cpu-thermal";
        soc = "/soc";
        txp = "/soc/txp@7e004000";
        dma = "/soc/dma@7e007000";
        watchdog = "/soc/watchdog@7e100000";
        pm = "/soc/watchdog@7e100000";
        clocks = "/soc/cprman@7e101000";
        random = "/soc/rng@7e104000";
        rng = "/soc/rng@7e104000";
        mailbox = "/soc/mailbox@7e00b880";
        gpio = "/soc/gpio@7e200000";
        dpi_gpio0 = "/soc/gpio@7e200000/dpi_gpio0";
        emmc_gpio22 = "/soc/gpio@7e200000/emmc_gpio22";
        emmc_gpio34 = "/soc/gpio@7e200000/emmc_gpio34";
        emmc_gpio48 = "/soc/gpio@7e200000/emmc_gpio48";
        gpclk0_gpio4 = "/soc/gpio@7e200000/gpclk0_gpio4";
        gpclk1_gpio5 = "/soc/gpio@7e200000/gpclk1_gpio5";
        gpclk1_gpio42 = "/soc/gpio@7e200000/gpclk1_gpio42";
        gpclk1_gpio44 = "/soc/gpio@7e200000/gpclk1_gpio44";
        gpclk2_gpio6 = "/soc/gpio@7e200000/gpclk2_gpio6";
        gpclk2_gpio43 = "/soc/gpio@7e200000/gpclk2_gpio43";
        i2c0_gpio0 = "/soc/gpio@7e200000/i2c0_gpio0";
        i2c0_gpio28 = "/soc/gpio@7e200000/i2c0_gpio28";
        i2c0_gpio44 = "/soc/gpio@7e200000/i2c0_gpio44";
        i2c1_gpio2 = "/soc/gpio@7e200000/i2c1_gpio2";
        i2c1_gpio44 = "/soc/gpio@7e200000/i2c1_gpio44";
        jtag_gpio22 = "/soc/gpio@7e200000/jtag_gpio22";
        pcm_gpio18 = "/soc/gpio@7e200000/pcm_gpio18";
        pcm_gpio28 = "/soc/gpio@7e200000/pcm_gpio28";
        pwm0_gpio12 = "/soc/gpio@7e200000/pwm0_gpio12";
        pwm0_gpio18 = "/soc/gpio@7e200000/pwm0_gpio18";
        pwm0_gpio40 = "/soc/gpio@7e200000/pwm0_gpio40";
        pwm1_gpio13 = "/soc/gpio@7e200000/pwm1_gpio13";
        pwm1_gpio19 = "/soc/gpio@7e200000/pwm1_gpio19";
        pwm1_gpio41 = "/soc/gpio@7e200000/pwm1_gpio41";
        pwm1_gpio45 = "/soc/gpio@7e200000/pwm1_gpio45";
        sdhost_pins = "/soc/gpio@7e200000/sdhost_gpio48";
        sdhost_gpio48 = "/soc/gpio@7e200000/sdhost_gpio48";
        spi0_gpio7 = "/soc/gpio@7e200000/spi0_gpio7";
        spi0_gpio35 = "/soc/gpio@7e200000/spi0_gpio35";
        spi1_gpio16 = "/soc/gpio@7e200000/spi1_gpio16";
        spi2_gpio40 = "/soc/gpio@7e200000/spi2_gpio40";
        uart0_gpio14 = "/soc/gpio@7e200000/uart0_gpio14";
        uart0_ctsrts_gpio16 = "/soc/gpio@7e200000/uart0_ctsrts_gpio16";
        uart0_ctsrts_gpio30 = "/soc/gpio@7e200000/uart0_ctsrts_gpio30";
        uart0_gpio32 = "/soc/gpio@7e200000/uart0_gpio32";
        uart0_gpio36 = "/soc/gpio@7e200000/uart0_gpio36";
        uart0_ctsrts_gpio38 = "/soc/gpio@7e200000/uart0_ctsrts_gpio38";
        uart1_gpio14 = "/soc/gpio@7e200000/uart1_gpio14";
        uart1_ctsrts_gpio16 = "/soc/gpio@7e200000/uart1_ctsrts_gpio16";
        uart1_gpio32 = "/soc/gpio@7e200000/uart1_gpio32";
        uart1_ctsrts_gpio30 = "/soc/gpio@7e200000/uart1_ctsrts_gpio30";
        uart1_gpio40 = "/soc/gpio@7e200000/uart1_gpio40";
        uart1_ctsrts_gpio42 = "/soc/gpio@7e200000/uart1_ctsrts_gpio42";
        gpclk0_gpio49 = "/soc/gpio@7e200000/gpclk0_gpio49";
        gpclk1_gpio50 = "/soc/gpio@7e200000/gpclk1_gpio50";
        gpclk2_gpio51 = "/soc/gpio@7e200000/gpclk2_gpio51";
        i2c0_gpio46 = "/soc/gpio@7e200000/i2c0_gpio46";
        i2c1_gpio46 = "/soc/gpio@7e200000/i2c1_gpio46";
        i2c3_gpio2 = "/soc/gpio@7e200000/i2c3_gpio2";
        i2c3_gpio4 = "/soc/gpio@7e200000/i2c3_gpio4";
        i2c4_gpio6 = "/soc/gpio@7e200000/i2c4_gpio6";
        i2c4_gpio8 = "/soc/gpio@7e200000/i2c4_gpio8";
        i2c5_gpio10 = "/soc/gpio@7e200000/i2c5_gpio10";
        i2c5_gpio12 = "/soc/gpio@7e200000/i2c5_gpio12";
        i2c6_gpio0 = "/soc/gpio@7e200000/i2c6_gpio0";
        i2c6_gpio22 = "/soc/gpio@7e200000/i2c6_gpio22";
        i2c_slave_gpio8 = "/soc/gpio@7e200000/i2c_slave_gpio8";
        jtag_gpio48 = "/soc/gpio@7e200000/jtag_gpio48";
        mii_gpio28 = "/soc/gpio@7e200000/mii_gpio28";
        mii_gpio36 = "/soc/gpio@7e200000/mii_gpio36";
        pcm_gpio50 = "/soc/gpio@7e200000/pcm_gpio50";
        pwm0_gpio52 = "/soc/gpio@7e200000/pwm0_gpio52";
        pwm1_gpio53 = "/soc/gpio@7e200000/pwm1_gpio53";
        rgmii_gpio35 = "/soc/gpio@7e200000/rgmii_gpio35";
        rgmii_irq_gpio34 = "/soc/gpio@7e200000/rgmii_irq_gpio34";
        rgmii_irq_gpio39 = "/soc/gpio@7e200000/rgmii_irq_gpio39";
        rgmii_mdio_gpio28 = "/soc/gpio@7e200000/rgmii_mdio_gpio28";
        rgmii_mdio_gpio37 = "/soc/gpio@7e200000/rgmii_mdio_gpio37";
        spi0_gpio46 = "/soc/gpio@7e200000/spi0_gpio46";
        spi2_gpio46 = "/soc/gpio@7e200000/spi2_gpio46";
        spi3_gpio0 = "/soc/gpio@7e200000/spi3_gpio0";
        spi4_gpio4 = "/soc/gpio@7e200000/spi4_gpio4";
        spi5_gpio12 = "/soc/gpio@7e200000/spi5_gpio12";
        spi6_gpio18 = "/soc/gpio@7e200000/spi6_gpio18";
        uart2_gpio0 = "/soc/gpio@7e200000/uart2_gpio0";
        uart2_ctsrts_gpio2 = "/soc/gpio@7e200000/uart2_ctsrts_gpio2";
        uart3_gpio4 = "/soc/gpio@7e200000/uart3_gpio4";
        uart3_ctsrts_gpio6 = "/soc/gpio@7e200000/uart3_ctsrts_gpio6";
        uart4_gpio8 = "/soc/gpio@7e200000/uart4_gpio8";
        uart4_ctsrts_gpio10 = "/soc/gpio@7e200000/uart4_ctsrts_gpio10";
        uart5_gpio12 = "/soc/gpio@7e200000/uart5_gpio12";
        uart5_ctsrts_gpio14 = "/soc/gpio@7e200000/uart5_ctsrts_gpio14";
        dpi_18bit_gpio0 = "/soc/gpio@7e200000/dpi_18bit_gpio0";
        gpioout = "/soc/gpio@7e200000/gpioout";
        alt0 = "/soc/gpio@7e200000/alt0";
        spi0_pins = "/soc/gpio@7e200000/spi0_pins";
        spi0_cs_pins = "/soc/gpio@7e200000/spi0_cs_pins";
        spi3_pins = "/soc/gpio@7e200000/spi3_pins";
        spi3_cs_pins = "/soc/gpio@7e200000/spi3_cs_pins";
        spi4_pins = "/soc/gpio@7e200000/spi4_pins";
        spi4_cs_pins = "/soc/gpio@7e200000/spi4_cs_pins";
        spi5_pins = "/soc/gpio@7e200000/spi5_pins";
        spi5_cs_pins = "/soc/gpio@7e200000/spi5_cs_pins";
        spi6_pins = "/soc/gpio@7e200000/spi6_pins";
        spi6_cs_pins = "/soc/gpio@7e200000/spi6_cs_pins";
        i2c0_pins = "/soc/gpio@7e200000/i2c0";
        i2c1_pins = "/soc/gpio@7e200000/i2c1";
        i2c3_pins = "/soc/gpio@7e200000/i2c3";
        i2c4_pins = "/soc/gpio@7e200000/i2c4";
        i2c5_pins = "/soc/gpio@7e200000/i2c5";
        i2c6_pins = "/soc/gpio@7e200000/i2c6";
        i2s_pins = "/soc/gpio@7e200000/i2s";
        sdio_pins = "/soc/gpio@7e200000/sdio_pins";
        bt_pins = "/soc/gpio@7e200000/bt_pins";
        uart0_pins = "/soc/gpio@7e200000/uart0_pins";
        uart1_pins = "/soc/gpio@7e200000/uart1_pins";
        uart2_pins = "/soc/gpio@7e200000/uart2_pins";
        uart3_pins = "/soc/gpio@7e200000/uart3_pins";
        uart4_pins = "/soc/gpio@7e200000/uart4_pins";
        uart5_pins = "/soc/gpio@7e200000/uart5_pins";
        audio_pins = "/soc/gpio@7e200000/audio_pins";
        uart0 = "/soc/serial@7e201000";
        sdhost = "/soc/mmc@7e202000";
        i2s = "/soc/i2s@7e203000";
        spi0 = "/soc/spi@7e204000";
        spi = "/soc/spi@7e204000";
        spidev0 = "/soc/spi@7e204000/spidev@0";
        spidev1 = "/soc/spi@7e204000/spidev@1";
        i2c0 = "/soc/i2c@7e205000";
        pixelvalve0 = "/soc/pixelvalve@7e206000";
        pixelvalve1 = "/soc/pixelvalve@7e207000";
        dpi = "/soc/dpi@7e208000";
        dsi0 = "/soc/dsi@7e209000";
        aux = "/soc/aux@7e215000";
        uart1 = "/soc/serial@7e215040";
        spi1 = "/soc/spi@7e215080";
        spi2 = "/soc/spi@7e2150c0";
        pwm = "/soc/pwm@7e20c000";
        hvs = "/soc/hvs@7e400000";
        dsi1 = "/soc/dsi@7e700000";
        csi0 = "/soc/csi@7e800000";
        csi1 = "/soc/csi@7e801000";
        i2c1 = "/soc/i2c@7e804000";
        i2c2 = "/soc/i2c@7e805000";
        vec = "/soc/vec@7e806000";
        pixelvalve2 = "/soc/pixelvalve@7e807000";
        hdmi = "/soc/hdmi@7e902000";
        usb = "/soc/usb@7e980000";
        vc4 = "/soc/gpu";
        local_intc = "/soc/local_intc@40000000";
        gicv2 = "/soc/gic400@40041000";
        thermal = "/soc/thermal@7d5d2200";
        uart2 = "/soc/serial@7e201400";
        uart3 = "/soc/serial@7e201600";
        uart4 = "/soc/serial@7e201800";
        uart5 = "/soc/serial@7e201a00";
        spi3 = "/soc/spi@7e204600";
        spi4 = "/soc/spi@7e204800";
        spi5 = "/soc/spi@7e204a00";
        spi6 = "/soc/spi@7e204c00";
        i2c3 = "/soc/i2c@7e205600";
        i2c4 = "/soc/i2c@7e205800";
        i2c5 = "/soc/i2c@7e205a00";
        i2c6 = "/soc/i2c@7e205c00";
        pwm1 = "/soc/pwm@7e20c800";
        emmc2 = "/soc/emmc2@7e340000";
        sdhci = "/soc/mmc@7e300000";
        mmc = "/soc/mmc@7e300000";
        mmcnr = "/soc/mmcnr@7e300000";
        firmwarekms = "/soc/firmwarekms@7e600000";
        smi = "/soc/smi@7e600000";
        axiperf = "/soc/axiperf";
        firmware = "/soc/firmware";
        expgpio = "/soc/firmware/gpio";
        power = "/soc/power";
        fb = "/soc/fb";
        vcsm = "/soc/vcsm";
        audio = "/soc/audio";
        sound = "/soc/sound";
        virtgpio = "/soc/virtgpio";
        clk_osc = "/clocks/clock@3";
        clk_usb = "/clocks/clock@4";
        usbphy = "/phy";
        cpus = "/cpus";
        cpu0 = "/cpus/cpu@0";
        cpu1 = "/cpus/cpu@1";
        cpu2 = "/cpus/cpu@2";
        cpu3 = "/cpus/cpu@3";
        v3d = "/v3dbus/v3d@7ec04000";
        scb = "/scb";
        pcie_0 = "/scb/pcie@7d500000";
        genet = "/scb/genet@7d580000";
        phy1 = "/scb/genet@7d580000/mdio@e14/genet-phy@0";
        dma40 = "/scb/dma@7e007b00";
        xhci = "/scb/xhci@7e9c0000";
        vchiq = "/scb/mailbox@7e00b840";
        leds = "/leds";
        act_led = "/leds/act";
        pwr_led = "/leds/pwr";
        vdd_3v3_reg = "/fixedregulator_3v3";
        vdd_5v0_reg = "/fixedregulator_5v0";
        sd_io_1v8_reg = "/sd_io_1v8_reg";
    };
};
